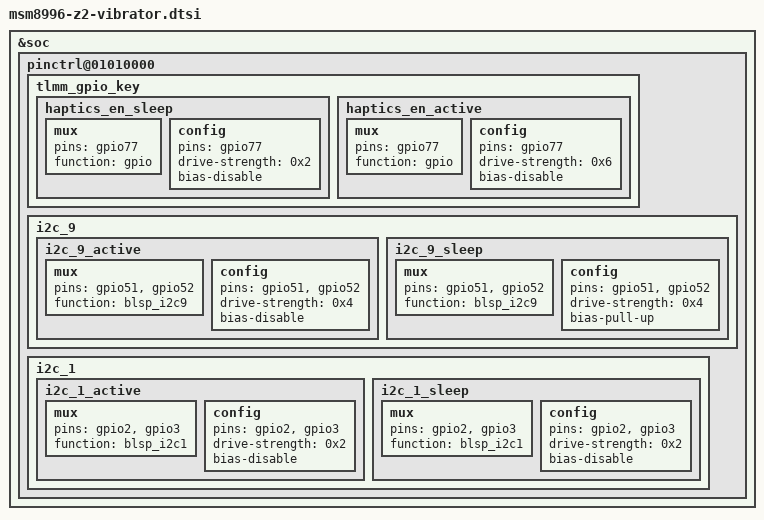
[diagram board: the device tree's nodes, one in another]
&soc {
	pinctrl@01010000 {
		tlmm_gpio_key {
			haptics_en_sleep {
				mux {
					pins = "gpio77";
					function = "gpio";
				};
				config {
					pins = "gpio77";
					drive-strength = <0x2>;
					bias-disable;
				};
			};
			haptics_en_active {
				mux {
					pins = "gpio77";
					function = "gpio";
				};
				config {
					pins = "gpio77";
					drive-strength = <0x6>;
					bias-disable;
				};
			};
		};
			i2c_9 {
				i2c_9_active {
					linux,phandle = <0xfc>;
					phandle = <0xfc>;
					mux {
						pins = "gpio51", "gpio52";
						function = "blsp_i2c9";
					};
					config {
						pins = "gpio51", "gpio52";
						drive-strength = <0x4>;
						bias-disable;
					};
				};
				i2c_9_sleep {
					linux,phandle = <0xfd>;
					phandle = <0xfd>;
					mux {
						pins = "gpio51", "gpio52";
						function = "blsp_i2c9";
					};
					config {
						pins = "gpio51", "gpio52";
						drive-strength = <0x4>;
						bias-pull-up;
					};
				};
			};
		i2c_1 {
			i2c_1_active {
				linux,phandle = <0xe4>;
				phandle = <0xe4>;
				mux {
					pins = "gpio2", "gpio3";
					function = "blsp_i2c1";
				};
				config {
					pins = "gpio2", "gpio3";
					drive-strength = <0x2>;
					bias-disable;
				};
			};
			i2c_1_sleep {
				linux,phandle = <0xe5>;
				phandle = <0xe5>;
				mux {
					pins = "gpio2", "gpio3";
					function = "blsp_i2c1";
				};
				config {
					pins = "gpio2", "gpio3";
					drive-strength = <0x2>;
					bias-disable;
				};
			};
		};
	};
};
